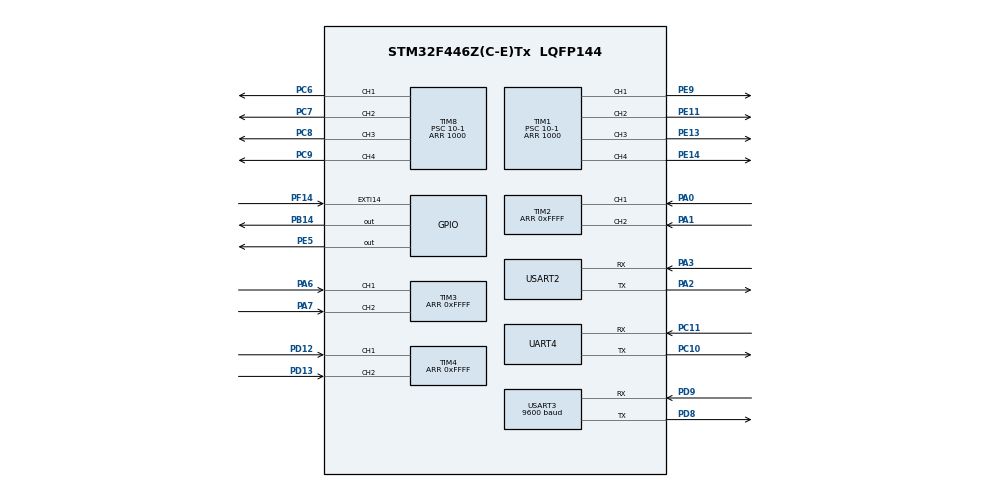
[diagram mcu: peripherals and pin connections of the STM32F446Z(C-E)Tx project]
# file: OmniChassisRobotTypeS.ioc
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Mcu.Family=STM32F4
Mcu.Name=STM32F446Z(C-E)Tx
Mcu.Package=LQFP144
NVIC.EXTI15_10_IRQn=true\:0\:0\:false\:false\:true\:true\:true
NVIC.PriorityGroup=NVIC_PRIORITYGROUP_4
NVIC.TIM6_DAC_IRQn=true\:0\:0\:false\:false\:true\:true\:true
NVIC.UART4_IRQn=true\:0\:0\:false\:false\:true\:true\:true
NVIC.USART2_IRQn=true\:0\:0\:false\:false\:true\:true\:true
NVIC.USART3_IRQn=true\:0\:0\:false\:false\:true\:true\:true
PA0-WKUP.GPIO_PuPd=GPIO_PULLUP
PA0-WKUP.Signal=S_TIM2_CH1_ETR
PA1.GPIO_PuPd=GPIO_PULLUP
PA1.Signal=S_TIM2_CH2
PA2.Mode=Asynchronous
PA2.Signal=USART2_TX
PA3.Mode=Asynchronous
PA3.Signal=USART2_RX
PA6.GPIO_PuPd=GPIO_PULLUP
PA6.Signal=S_TIM3_CH1
PA7.GPIO_PuPd=GPIO_PULLUP
PA7.Signal=S_TIM3_CH2
PB14.Signal=GPIO_Output
PC10.Mode=Asynchronous
PC10.Signal=UART4_TX
PC11.Mode=Asynchronous
PC11.Signal=UART4_RX
PC6.Signal=S_TIM8_CH1
PC7.Signal=S_TIM8_CH2
PC8.Signal=S_TIM8_CH3
PC9.Signal=S_TIM8_CH4
PD12.GPIO_PuPd=GPIO_PULLUP
PD12.Signal=S_TIM4_CH1
PD13.GPIO_PuPd=GPIO_PULLUP
PD13.Signal=S_TIM4_CH2
PD8.Mode=Asynchronous
PD8.Signal=USART3_TX
PD9.Mode=Asynchronous
PD9.Signal=USART3_RX
PE11.Signal=S_TIM1_CH2
PE13.Signal=S_TIM1_CH3
PE14.Signal=S_TIM1_CH4
PE5.Signal=GPIO_Output
PE9.Signal=S_TIM1_CH1
PF14.GPIO_ModeDefaultEXTI=GPIO_MODE_IT_RISING_FALLING
PF14.GPIO_PuPd=GPIO_PULLUP
PF14.Signal=GPXTI14
ProjectManager.HeapSize=0x200
ProjectManager.StackSize=0x400
ProjectManager.TargetToolchain=STM32CubeIDE
RCC.CortexFreq_Value=16000000
RCC.USBFreq_Value=96000000
RCC.VCOOutputFreq_Value=192000000
SH.S_TIM1_CH1.0=TIM1_CH1,PWM Generation1 CH1
SH.S_TIM1_CH2.0=TIM1_CH2,PWM Generation2 CH2
SH.S_TIM1_CH3.0=TIM1_CH3,PWM Generation3 CH3
SH.S_TIM1_CH4.0=TIM1_CH4,PWM Generation4 CH4
SH.S_TIM2_CH1_ETR.0=TIM2_CH1,Encoder_Interface
SH.S_TIM2_CH2.0=TIM2_CH2,Encoder_Interface
SH.S_TIM3_CH1.0=TIM3_CH1,Encoder_Interface
SH.S_TIM3_CH2.0=TIM3_CH2,Encoder_Interface
SH.S_TIM4_CH1.0=TIM4_CH1,Encoder_Interface
SH.S_TIM4_CH2.0=TIM4_CH2,Encoder_Interface
SH.S_TIM8_CH1.0=TIM8_CH1,PWM Generation1 CH1
SH.S_TIM8_CH2.0=TIM8_CH2,PWM Generation2 CH2
SH.S_TIM8_CH3.0=TIM8_CH3,PWM Generation3 CH3
SH.S_TIM8_CH4.0=TIM8_CH4,PWM Generation4 CH4
TIM1.Channel-PWM\ Generation1\ CH1=TIM_CHANNEL_1
TIM1.Channel-PWM\ Generation2\ CH2=TIM_CHANNEL_2
TIM1.Channel-PWM\ Generation3\ CH3=TIM_CHANNEL_3
TIM1.Channel-PWM\ Generation4\ CH4=TIM_CHANNEL_4
TIM1.Period=1000
TIM1.Prescaler=10-1
TIM2.EncoderMode=TIM_ENCODERMODE_TI12
TIM2.Period=0xFFFF
TIM3.EncoderMode=TIM_ENCODERMODE_TI12
TIM3.Period=0xFFFF
TIM4.EncoderMode=TIM_ENCODERMODE_TI12
TIM4.Period=0xFFFF
TIM8.Channel-PWM\ Generation1\ CH1=TIM_CHANNEL_1
TIM8.Channel-PWM\ Generation2\ CH2=TIM_CHANNEL_2
TIM8.Channel-PWM\ Generation3\ CH3=TIM_CHANNEL_3
TIM8.Channel-PWM\ Generation4\ CH4=TIM_CHANNEL_4
TIM8.Period=1000
TIM8.Prescaler=10-1
UART4.VirtualMode=Asynchronous
USART2.VirtualMode=VM_ASYNC
USART3.BaudRate=9600
USART3.VirtualMode=VM_ASYNC
VP_TIM6_VS_ClockSourceINT.Mode=Enable_Timer
board=custom

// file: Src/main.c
/* USER CODE BEGIN Header */
/**
  ******************************************************************************
  * @file           : main.c
  * @brief          : Main program body
  ******************************************************************************
  * @attention
  *
  * <h2><center>&copy; Copyright (c) 2020 STMicroelectronics.
  * All rights reserved.</center></h2>
  *
  * This software component is licensed by ST under BSD 3-Clause license,
  * the "License"; You may not use this file except in compliance with the
  * License. You may obtain a copy of the License at:
  *                        opensource.org/licenses/BSD-3-Clause
  *
  ******************************************************************************
  */
/* USER CODE END Header */

#include "main.h"

/* USER CODE BEGIN Includes */
#include "../stm_interface/easy_main.h"

/* USER CODE END Includes */

TIM_HandleTypeDef htim1;
TIM_HandleTypeDef htim2;
TIM_HandleTypeDef htim3;
TIM_HandleTypeDef htim4;
TIM_HandleTypeDef htim6;
TIM_HandleTypeDef htim8;

UART_HandleTypeDef huart4;
UART_HandleTypeDef huart2;
UART_HandleTypeDef huart3;

void SystemClock_Config(void);
static void MX_GPIO_Init(void);
static void MX_TIM1_Init(void);
static void MX_TIM2_Init(void);
static void MX_TIM3_Init(void);
static void MX_TIM4_Init(void);
static void MX_TIM6_Init(void);
static void MX_TIM8_Init(void);
static void MX_UART4_Init(void);
static void MX_USART2_UART_Init(void);
static void MX_USART3_UART_Init(void);

int main(void)
{

  /* MCU Configuration--------------------------------------------------------*/

  /* Reset of all peripherals, Initializes the Flash interface and the Systick. */
  HAL_Init();

  /* Configure the system clock */
  SystemClock_Config();

  /* Initialize all configured peripherals */
  MX_GPIO_Init();
  MX_TIM1_Init();
  MX_TIM2_Init();
  MX_TIM3_Init();
  MX_TIM4_Init();
  MX_TIM6_Init();
  MX_TIM8_Init();
  MX_UART4_Init();
  MX_USART2_UART_Init();
  MX_USART3_UART_Init();
  /* USER CODE BEGIN 2 */
  easy_setup();
  /* USER CODE END 2 */

  /* Infinite loop */
  /* USER CODE BEGIN WHILE */
  while (1)
  {
	easy_loop();
    /* USER CODE END WHILE */

  }
}

void SystemClock_Config(void)
{
  RCC_OscInitTypeDef RCC_OscInitStruct = {0};
  RCC_ClkInitTypeDef RCC_ClkInitStruct = {0};

  /** Configure the main internal regulator output voltage
  */
  __HAL_RCC_PWR_CLK_ENABLE();
  __HAL_PWR_VOLTAGESCALING_CONFIG(PWR_REGULATOR_VOLTAGE_SCALE3);
  /** Initializes the CPU, AHB and APB busses clocks
  */
  RCC_OscInitStruct.OscillatorType = RCC_OSCILLATORTYPE_HSI;
  RCC_OscInitStruct.HSIState = RCC_HSI_ON;
  RCC_OscInitStruct.HSICalibrationValue = RCC_HSICALIBRATION_DEFAULT;
  RCC_OscInitStruct.PLL.PLLState = RCC_PLL_NONE;
  if (HAL_RCC_OscConfig(&RCC_OscInitStruct) != HAL_OK)
  {
    Error_Handler();
  }
  /** Initializes the CPU, AHB and APB busses clocks
  */
  RCC_ClkInitStruct.ClockType = RCC_CLOCKTYPE_HCLK|RCC_CLOCKTYPE_SYSCLK
                              |RCC_CLOCKTYPE_PCLK1|RCC_CLOCKTYPE_PCLK2;
  RCC_ClkInitStruct.SYSCLKSource = RCC_SYSCLKSOURCE_HSI;
  RCC_ClkInitStruct.AHBCLKDivider = RCC_SYSCLK_DIV1;
  RCC_ClkInitStruct.APB1CLKDivider = RCC_HCLK_DIV1;
  RCC_ClkInitStruct.APB2CLKDivider = RCC_HCLK_DIV1;

  if (HAL_RCC_ClockConfig(&RCC_ClkInitStruct, FLASH_LATENCY_0) != HAL_OK)
  {
    Error_Handler();
  }
}

static void MX_TIM1_Init(void)
{

  TIM_MasterConfigTypeDef sMasterConfig = {0};
  TIM_OC_InitTypeDef sConfigOC = {0};
  TIM_BreakDeadTimeConfigTypeDef sBreakDeadTimeConfig = {0};

  htim1.Instance = TIM1;
  htim1.Init.Prescaler = 10-1;
  htim1.Init.CounterMode = TIM_COUNTERMODE_UP;
  htim1.Init.Period = 1000;
  htim1.Init.ClockDivision = TIM_CLOCKDIVISION_DIV1;
  htim1.Init.RepetitionCounter = 0;
  htim1.Init.AutoReloadPreload = TIM_AUTORELOAD_PRELOAD_DISABLE;
  if (HAL_TIM_PWM_Init(&htim1) != HAL_OK)
  {
    Error_Handler();
  }
  sMasterConfig.MasterOutputTrigger = TIM_TRGO_RESET;
  sMasterConfig.MasterSlaveMode = TIM_MASTERSLAVEMODE_DISABLE;
  if (HAL_TIMEx_MasterConfigSynchronization(&htim1, &sMasterConfig) != HAL_OK)
  {
    Error_Handler();
  }
  sConfigOC.OCMode = TIM_OCMODE_PWM1;
  sConfigOC.Pulse = 0;
  sConfigOC.OCPolarity = TIM_OCPOLARITY_HIGH;
  sConfigOC.OCNPolarity = TIM_OCNPOLARITY_HIGH;
  sConfigOC.OCFastMode = TIM_OCFAST_DISABLE;
  sConfigOC.OCIdleState = TIM_OCIDLESTATE_RESET;
  sConfigOC.OCNIdleState = TIM_OCNIDLESTATE_RESET;
  if (HAL_TIM_PWM_ConfigChannel(&htim1, &sConfigOC, TIM_CHANNEL_1) != HAL_OK)
  {
    Error_Handler();
  }
  if (HAL_TIM_PWM_ConfigChannel(&htim1, &sConfigOC, TIM_CHANNEL_2) != HAL_OK)
  {
    Error_Handler();
  }
  if (HAL_TIM_PWM_ConfigChannel(&htim1, &sConfigOC, TIM_CHANNEL_3) != HAL_OK)
  {
    Error_Handler();
  }
  if (HAL_TIM_PWM_ConfigChannel(&htim1, &sConfigOC, TIM_CHANNEL_4) != HAL_OK)
  {
    Error_Handler();
  }
  sBreakDeadTimeConfig.OffStateRunMode = TIM_OSSR_DISABLE;
  sBreakDeadTimeConfig.OffStateIDLEMode = TIM_OSSI_DISABLE;
  sBreakDeadTimeConfig.LockLevel = TIM_LOCKLEVEL_OFF;
  sBreakDeadTimeConfig.DeadTime = 0;
  sBreakDeadTimeConfig.BreakState = TIM_BREAK_DISABLE;
  sBreakDeadTimeConfig.BreakPolarity = TIM_BREAKPOLARITY_HIGH;
  sBreakDeadTimeConfig.AutomaticOutput = TIM_AUTOMATICOUTPUT_DISABLE;
  if (HAL_TIMEx_ConfigBreakDeadTime(&htim1, &sBreakDeadTimeConfig) != HAL_OK)
  {
    Error_Handler();
  }
  HAL_TIM_MspPostInit(&htim1);

}

static void MX_TIM2_Init(void)
{

  TIM_Encoder_InitTypeDef sConfig = {0};
  TIM_MasterConfigTypeDef sMasterConfig = {0};

  htim2.Instance = TIM2;
  htim2.Init.Prescaler = 0;
  htim2.Init.CounterMode = TIM_COUNTERMODE_UP;
  htim2.Init.Period = 0xFFFF;
  htim2.Init.ClockDivision = TIM_CLOCKDIVISION_DIV1;
  htim2.Init.AutoReloadPreload = TIM_AUTORELOAD_PRELOAD_DISABLE;
  sConfig.EncoderMode = TIM_ENCODERMODE_TI12;
  sConfig.IC1Polarity = TIM_ICPOLARITY_RISING;
  sConfig.IC1Selection = TIM_ICSELECTION_DIRECTTI;
  sConfig.IC1Prescaler = TIM_ICPSC_DIV1;
  sConfig.IC1Filter = 0;
  sConfig.IC2Polarity = TIM_ICPOLARITY_RISING;
  sConfig.IC2Selection = TIM_ICSELECTION_DIRECTTI;
  sConfig.IC2Prescaler = TIM_ICPSC_DIV1;
  sConfig.IC2Filter = 0;
  if (HAL_TIM_Encoder_Init(&htim2, &sConfig) != HAL_OK)
  {
    Error_Handler();
  }
  sMasterConfig.MasterOutputTrigger = TIM_TRGO_RESET;
  sMasterConfig.MasterSlaveMode = TIM_MASTERSLAVEMODE_DISABLE;
  if (HAL_TIMEx_MasterConfigSynchronization(&htim2, &sMasterConfig) != HAL_OK)
  {
    Error_Handler();
  }

}

static void MX_TIM3_Init(void)
{

  TIM_Encoder_InitTypeDef sConfig = {0};
  TIM_MasterConfigTypeDef sMasterConfig = {0};

  htim3.Instance = TIM3;
  htim3.Init.Prescaler = 0;
  htim3.Init.CounterMode = TIM_COUNTERMODE_UP;
  htim3.Init.Period = 0xFFFF;
  htim3.Init.ClockDivision = TIM_CLOCKDIVISION_DIV1;
  htim3.Init.AutoReloadPreload = TIM_AUTORELOAD_PRELOAD_DISABLE;
  sConfig.EncoderMode = TIM_ENCODERMODE_TI12;
  sConfig.IC1Polarity = TIM_ICPOLARITY_RISING;
  sConfig.IC1Selection = TIM_ICSELECTION_DIRECTTI;
  sConfig.IC1Prescaler = TIM_ICPSC_DIV1;
  sConfig.IC1Filter = 0;
  sConfig.IC2Polarity = TIM_ICPOLARITY_RISING;
  sConfig.IC2Selection = TIM_ICSELECTION_DIRECTTI;
  sConfig.IC2Prescaler = TIM_ICPSC_DIV1;
  sConfig.IC2Filter = 0;
  if (HAL_TIM_Encoder_Init(&htim3, &sConfig) != HAL_OK)
  {
    Error_Handler();
  }
  sMasterConfig.MasterOutputTrigger = TIM_TRGO_RESET;
  sMasterConfig.MasterSlaveMode = TIM_MASTERSLAVEMODE_DISABLE;
  if (HAL_TIMEx_MasterConfigSynchronization(&htim3, &sMasterConfig) != HAL_OK)
  {
    Error_Handler();
  }

}

static void MX_TIM4_Init(void)
{

  TIM_Encoder_InitTypeDef sConfig = {0};
  TIM_MasterConfigTypeDef sMasterConfig = {0};

  htim4.Instance = TIM4;
  htim4.Init.Prescaler = 0;
  htim4.Init.CounterMode = TIM_COUNTERMODE_UP;
  htim4.Init.Period = 0xFFFF;
  htim4.Init.ClockDivision = TIM_CLOCKDIVISION_DIV1;
  htim4.Init.AutoReloadPreload = TIM_AUTORELOAD_PRELOAD_DISABLE;
  sConfig.EncoderMode = TIM_ENCODERMODE_TI12;
  sConfig.IC1Polarity = TIM_ICPOLARITY_RISING;
  sConfig.IC1Selection = TIM_ICSELECTION_DIRECTTI;
  sConfig.IC1Prescaler = TIM_ICPSC_DIV1;
  sConfig.IC1Filter = 0;
  sConfig.IC2Polarity = TIM_ICPOLARITY_RISING;
  sConfig.IC2Selection = TIM_ICSELECTION_DIRECTTI;
  sConfig.IC2Prescaler = TIM_ICPSC_DIV1;
  sConfig.IC2Filter = 0;
  if (HAL_TIM_Encoder_Init(&htim4, &sConfig) != HAL_OK)
  {
    Error_Handler();
  }
  sMasterConfig.MasterOutputTrigger = TIM_TRGO_RESET;
  sMasterConfig.MasterSlaveMode = TIM_MASTERSLAVEMODE_DISABLE;
  if (HAL_TIMEx_MasterConfigSynchronization(&htim4, &sMasterConfig) != HAL_OK)
  {
    Error_Handler();
  }

}

static void MX_TIM6_Init(void)
{

  TIM_MasterConfigTypeDef sMasterConfig = {0};

  htim6.Instance = TIM6;
  htim6.Init.Prescaler = 0;
  htim6.Init.CounterMode = TIM_COUNTERMODE_UP;
  htim6.Init.Period = 0;
  htim6.Init.AutoReloadPreload = TIM_AUTORELOAD_PRELOAD_DISABLE;
  if (HAL_TIM_Base_Init(&htim6) != HAL_OK)
  {
    Error_Handler();
  }
  sMasterConfig.MasterOutputTrigger = TIM_TRGO_RESET;
  sMasterConfig.MasterSlaveMode = TIM_MASTERSLAVEMODE_DISABLE;
  if (HAL_TIMEx_MasterConfigSynchronization(&htim6, &sMasterConfig) != HAL_OK)
  {
    Error_Handler();
  }

}

static void MX_TIM8_Init(void)
{

  TIM_MasterConfigTypeDef sMasterConfig = {0};
  TIM_OC_InitTypeDef sConfigOC = {0};
  TIM_BreakDeadTimeConfigTypeDef sBreakDeadTimeConfig = {0};

  htim8.Instance = TIM8;
  htim8.Init.Prescaler = 10-1;
  htim8.Init.CounterMode = TIM_COUNTERMODE_UP;
  htim8.Init.Period = 1000;
  htim8.Init.ClockDivision = TIM_CLOCKDIVISION_DIV1;
  htim8.Init.RepetitionCounter = 0;
  htim8.Init.AutoReloadPreload = TIM_AUTORELOAD_PRELOAD_DISABLE;
  if (HAL_TIM_PWM_Init(&htim8) != HAL_OK)
  {
    Error_Handler();
  }
  sMasterConfig.MasterOutputTrigger = TIM_TRGO_RESET;
  sMasterConfig.MasterSlaveMode = TIM_MASTERSLAVEMODE_DISABLE;
  if (HAL_TIMEx_MasterConfigSynchronization(&htim8, &sMasterConfig) != HAL_OK)
  {
    Error_Handler();
  }
  sConfigOC.OCMode = TIM_OCMODE_PWM1;
  sConfigOC.Pulse = 0;
  sConfigOC.OCPolarity = TIM_OCPOLARITY_HIGH;
  sConfigOC.OCNPolarity = TIM_OCNPOLARITY_HIGH;
  sConfigOC.OCFastMode = TIM_OCFAST_DISABLE;
  sConfigOC.OCIdleState = TIM_OCIDLESTATE_RESET;
  sConfigOC.OCNIdleState = TIM_OCNIDLESTATE_RESET;
  if (HAL_TIM_PWM_ConfigChannel(&htim8, &sConfigOC, TIM_CHANNEL_1) != HAL_OK)
  {
    Error_Handler();
  }
  if (HAL_TIM_PWM_ConfigChannel(&htim8, &sConfigOC, TIM_CHANNEL_2) != HAL_OK)
  {
    Error_Handler();
  }
  if (HAL_TIM_PWM_ConfigChannel(&htim8, &sConfigOC, TIM_CHANNEL_3) != HAL_OK)
  {
    Error_Handler();
  }
  if (HAL_TIM_PWM_ConfigChannel(&htim8, &sConfigOC, TIM_CHANNEL_4) != HAL_OK)
  {
    Error_Handler();
  }
  sBreakDeadTimeConfig.OffStateRunMode = TIM_OSSR_DISABLE;
  sBreakDeadTimeConfig.OffStateIDLEMode = TIM_OSSI_DISABLE;
  sBreakDeadTimeConfig.LockLevel = TIM_LOCKLEVEL_OFF;
  sBreakDeadTimeConfig.DeadTime = 0;
  sBreakDeadTimeConfig.BreakState = TIM_BREAK_DISABLE;
  sBreakDeadTimeConfig.BreakPolarity = TIM_BREAKPOLARITY_HIGH;
  sBreakDeadTimeConfig.AutomaticOutput = TIM_AUTOMATICOUTPUT_DISABLE;
  if (HAL_TIMEx_ConfigBreakDeadTime(&htim8, &sBreakDeadTimeConfig) != HAL_OK)
  {
    Error_Handler();
  }
  HAL_TIM_MspPostInit(&htim8);

}

static void MX_UART4_Init(void)
{

  huart4.Instance = UART4;
  huart4.Init.BaudRate = 115200;
  huart4.Init.WordLength = UART_WORDLENGTH_8B;
  huart4.Init.StopBits = UART_STOPBITS_1;
  huart4.Init.Parity = UART_PARITY_NONE;
  huart4.Init.Mode = UART_MODE_TX_RX;
  huart4.Init.HwFlowCtl = UART_HWCONTROL_NONE;
  huart4.Init.OverSampling = UART_OVERSAMPLING_16;
  if (HAL_UART_Init(&huart4) != HAL_OK)
  {
    Error_Handler();
  }

}

static void MX_USART2_UART_Init(void)
{

  huart2.Instance = USART2;
  huart2.Init.BaudRate = 115200;
  huart2.Init.WordLength = UART_WORDLENGTH_8B;
  huart2.Init.StopBits = UART_STOPBITS_1;
  huart2.Init.Parity = UART_PARITY_NONE;
  huart2.Init.Mode = UART_MODE_TX_RX;
  huart2.Init.HwFlowCtl = UART_HWCONTROL_NONE;
  huart2.Init.OverSampling = UART_OVERSAMPLING_16;
  if (HAL_UART_Init(&huart2) != HAL_OK)
  {
    Error_Handler();
  }

}

static void MX_USART3_UART_Init(void)
{

  huart3.Instance = USART3;
  huart3.Init.BaudRate = 9600;
  huart3.Init.WordLength = UART_WORDLENGTH_8B;
  huart3.Init.StopBits = UART_STOPBITS_1;
  huart3.Init.Parity = UART_PARITY_NONE;
  huart3.Init.Mode = UART_MODE_TX_RX;
  huart3.Init.HwFlowCtl = UART_HWCONTROL_NONE;
  huart3.Init.OverSampling = UART_OVERSAMPLING_16;
  if (HAL_UART_Init(&huart3) != HAL_OK)
  {
    Error_Handler();
  }

}

static void MX_GPIO_Init(void)
{
  GPIO_InitTypeDef GPIO_InitStruct = {0};

  /* GPIO Ports Clock Enable */
  __HAL_RCC_GPIOE_CLK_ENABLE();
  __HAL_RCC_GPIOA_CLK_ENABLE();
  __HAL_RCC_GPIOF_CLK_ENABLE();
  __HAL_RCC_GPIOB_CLK_ENABLE();
  __HAL_RCC_GPIOD_CLK_ENABLE();
  __HAL_RCC_GPIOC_CLK_ENABLE();

  /*Configure GPIO pin Output Level */
  HAL_GPIO_WritePin(GPIOE, GPIO_PIN_5, GPIO_PIN_RESET);

  /*Configure GPIO pin Output Level */
  HAL_GPIO_WritePin(GPIOB, GPIO_PIN_14, GPIO_PIN_RESET);

  /*Configure GPIO pin : PE5 */
  GPIO_InitStruct.Pin = GPIO_PIN_5;
  GPIO_InitStruct.Mode = GPIO_MODE_OUTPUT_PP;
  GPIO_InitStruct.Pull = GPIO_NOPULL;
  GPIO_InitStruct.Speed = GPIO_SPEED_FREQ_LOW;
  HAL_GPIO_Init(GPIOE, &GPIO_InitStruct);

  /*Configure GPIO pin : PF14 */
  GPIO_InitStruct.Pin = GPIO_PIN_14;
  GPIO_InitStruct.Mode = GPIO_MODE_IT_RISING_FALLING;
  GPIO_InitStruct.Pull = GPIO_PULLUP;
  HAL_GPIO_Init(GPIOF, &GPIO_InitStruct);

  /*Configure GPIO pin : PB14 */
  GPIO_InitStruct.Pin = GPIO_PIN_14;
  GPIO_InitStruct.Mode = GPIO_MODE_OUTPUT_PP;
  GPIO_InitStruct.Pull = GPIO_NOPULL;
  GPIO_InitStruct.Speed = GPIO_SPEED_FREQ_LOW;
  HAL_GPIO_Init(GPIOB, &GPIO_InitStruct);

  /* EXTI interrupt init*/
  HAL_NVIC_SetPriority(EXTI15_10_IRQn, 0, 0);
  HAL_NVIC_EnableIRQ(EXTI15_10_IRQn);

}

void Error_Handler(void)
{
}

/************************ (C) COPYRIGHT STMicroelectronics *****END OF FILE****/
